# rCSL_vpif_001 register map
Vendor: Texas Instruments
Peripheral module from a debugger description file (folder OMAPL138_C6748).
Registers are 32-bit, access not given, reset 0x0 unless marked. A register's access mark holds for its fields unless they carry their own. Offsets are as the file gives them; lines under a group give offsets from that group; [hi:lo] are bit positions; {n}, {i} and the like mark numbered series; 'fields as' and 'values as' point back to an identical list; <NAME> marks a mode.

## VPIF
0x00 REVID ro reset 0x4C080A01 — VPIF Identification
  [31:0] REV
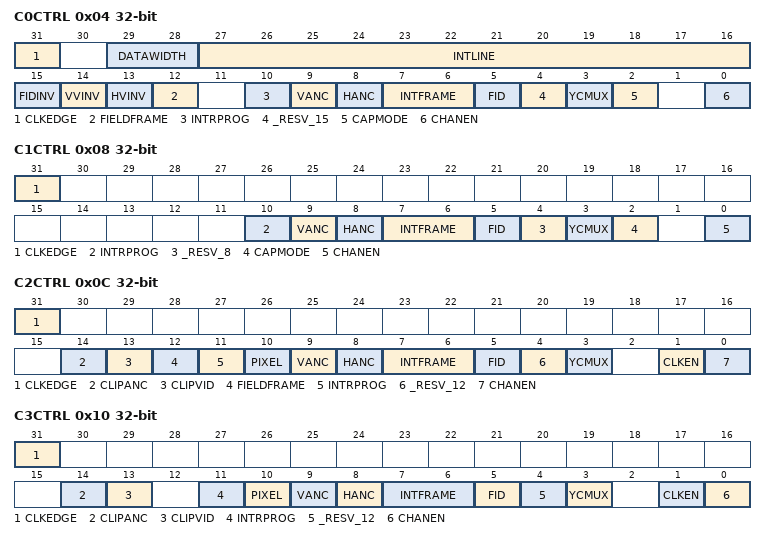
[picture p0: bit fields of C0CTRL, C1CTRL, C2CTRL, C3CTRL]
0x04 C0CTRL — Channel#0 control register
  [31] CLKEDGE rw — This register defines timing relationship between data phase and clock edge for video input data which is connected to VPIF channel 0 (at the chip-pin level). Edge control is carried out outside the module (just register signal is only asserted from the module) 0: data phase is changed at rising edge of the input clock 1: data phase is changed at falling edge of the input clock
    0=RISE (data phase is changed at rising edge of the input clock); 1=FALL (data phase is changed at falling edge of the input clock)
  [29:28] DATAWIDTH rw — Data bit width 00: 8 bit/pixel 01: 10 bit/pixel 10: 12 bit/pixel
    0=8BIT (8-bit format); 1=10BIT (10-bit format); 2=12BIT (12-bit format)
  [27:16] INTLINE rw — Line interrrupt interval
  [15] FIDINV rw — Field ID polarity
    0=DISABLE (No inversion); 1=ENABLE (Invert incoming field ID signal inside the module)
  [14] VVINV rw — Vertical pixel valid signal polarity control
    0=DISABLE (No inversion); 1=ENABLE (Invert incoming vertical pixel valid signal inside the module)
  [13] HVINV rw — Horizontal pixel valid signal polarity control
    0=DISABLE (No inversion); 1=ENABLE (Invert incoming horizontal pixel valid signal inside the module)
  [12] FIELDFRAME rw — SDRAM storage mode of input picture
    0=FIELD (Field storage); 1=FRAME (Frame storage)
  [10] INTRPROG rw — Output display format
    0=INTERLACED (Interlaced, 60 field/sec); 1=PROGRESSIVE (Progressive, 30 frame/sec)
  [9] VANC rw — Channel#0 Vertical Ancillary data enable 0:Vertical ancillary Data not supported 1:Vertical ancillary data is supported
    0=DISABLE (Vertical ancillary data disable); 1=ENABLE (Vertical ancillary data enable)
  [8] HANC rw — Channel#0 Horizontal Ancillary data enable 0: Horizontal ancillary Data not supported 1:Horizontal ancillary data is supported
    0=DISABLE (Horizontal ancillary data disable); 1=ENABLE (Horizontal ancillary data enable)
  [7:6] INTFRAME rw — Channel#0 Frame level interrupt to CPU 00: top field V-sync only 01: bottom field V-sync only 10: both top and bottom field V-sync 11: Reserved
    0=TOP (Top field V-sync only); 1=BOTTOM (Bottom field V-sync); 2=BOTH (Top and Bottom field)
  [5] FID ro — Channel#0 Field Identification
    0=TOP; 1=BOTTOM
  [4] _RESV_15 — SDRAM address format control register 0: raster scanning mode 1: sub-picture mode (access N)
  [3] YCMUX rw — Channel#0 input data format 0: Y/C non-multiplexed mode 1: Y/C multiplexed mode
    0=DISABLE (Channel#0 Non-multiplexed Y/C); 1=ENABLE (Channel#0 Y/C multiplexed)
  [2] CAPMODE rw — Channel#0 data mode to be processed 0x: BT. video (Y/C format) capture mode (sync signal is multiplexed). 1x: CCD/CMOS data capture mode (sync signal is independently prepared).
    0=BTYC (BT. video (Y/C format) capture mode); 1=CCDCMOS (CCD/CMOS data capture mode)
  [0] CHANEN rw — Channel#0 VPIF enable 0: Channel#0 VPIF module inactivated 1: Channel#0 VPIF module activated
    0=DISABLE (Channel#0 disable); 1=ENABLE (Channel#0 enable)
0x08 C1CTRL — Channel#1 control register
  [31] CLKEDGE rw — This register defines timing relationship between data phase and clock edge for video input data which is connected to VPIF channel 1 (at the chip-pin level). Edge control is carried out outside the module (just register signal is only asserted from the module) 0: data phase is changed at rising edge of the input clock 1: data phase is changed at falling edge of the input clock
    values as C0CTRL.CLKEDGE
  [10] INTRPROG rw — Output display format 0: Interlaced (60 [field/sec]) format. 1: Progressive (30 [frame/sec]) format.
    values as C0CTRL.INTRPROG
  [9] VANC rw — Channel#1 Vertical Ancillary data enable 0: Vertical Ancillary Data not supported 1: Vertical ancillary data is supported
    0=DISABLE (Vertical ancillary data disable); 1=ENABLE (Veritical ancillary data enable)
  [8] HANC rw — Channel#1 Horizontal Ancillary data enable 0: Horizontal ancillary Data not supported 1:Horizontal ancillary data is supported
    values as C0CTRL.HANC
  [7:6] INTFRAME rw — Channel#1 Frame level interrupt to CPU 00: top field V-sync only 01: bottom field V-sync only 10: both top and bottom field V-sync 11: Reserved
    values as C0CTRL.INTFRAME
  [5] FID ro — Channel#1 Field Identification
    0=TOP; 1=BOTTOM
  [4] _RESV_8 — SDRAM address format control register 0: raster scanning mode 1: sub-picture mode (access N)
  [3] YCMUX rw — Channel#1 input data format 0: Y/C non-multiplexed mode 1: Y/C multiplexed mode
    0=DISABLE (Channel#1 Non-multiplexed Y/C); 1=ENABLE (Channel#1 Y/C multiplexed)
  [2] CAPMODE rw — Channel#1 data mode to be processed 0x: BT. video (Y/C format) capture mode (sync signal is multiplexed). 1x: CCD/CMOS data capture mode (sync signal is independently prepared).
    values as C0CTRL.CAPMODE
  [0] CHANEN rw — Channel#1 VPIF enable 0: Channel#1 VPIF module inactivated 1: Channel#1 VPIF module activated
    0=DISABLE (Channel#1 disable); 1=ENABLE (Channel#1 enable)
0x0C C2CTRL — Channel#2 control register
  [31] CLKEDGE rw — This register defines timing relationship between data phase and clock edge for video output data which is connected to VPIF channel 2 (at the chip-pin level). Edge control is carried out outside the module (just register signal is only asserted from the module) 0: data phase is changed at rising edge of the input clock 1: data phase is changed at falling edge of the input clock
    values as C0CTRL.CLKEDGE
  [14] CLIPANC rw — Enable clipping support for ancillary data
    0=DISABLE; 1=ENABLE
  [13] CLIPVID rw — Enable clipping support for active video
    0=DISABLE; 1=ENABLE
  [12] FIELDFRAME rw — SDRAM storage mode of output picture 0: field independently stored. 1: frame based.
    0=FIELD (Field storage); 1=FRAME (Frame storage)
  [11] INTRPROG rw — Output display format 0: Interlaced (60 [field/sec]) format. 1: Progressive (30 [frame/sec]) format.
    values as C0CTRL.INTRPROG
  [10] PIXEL rw — Pixel data enable or disable 0: Pixel data disabled 1: Pixel data enabled
    0=DISABLE (Pixel data disabled); 1=ENABLE (Pixel data enabled)
  [9] VANC rw — Channel#2 Vertical Ancillary data enable 0: Vertical Ancillary Data not supported 1: Vertical ancillary data is supported
    values as C1CTRL.VANC
  [8] HANC rw — Channel#2 Horizontal Ancillary data enable 0: Horizontal ancillary Data not supported 1:Horizontal ancillary data is supported
    values as C0CTRL.HANC
  [7:6] INTFRAME rw — Channel#2 Frame level interrupt to CPU 00: top field V-sync only 01: bottom field V-sync only 10: both top and bottom field V-sync 11: Reserved
    values as C0CTRL.INTFRAME
  [5] FID ro — Channel#2 Field Identification
    0=TOP; 1=BOTTOM
  [4] _RESV_12 — SDRAM address format control register 0: raster scanning mode 1: sub-picture mode (access N)
  [3] YCMUX rw — Channel#2 data format to be transmitted 0: Y/C non-multiplexed mode 1: Y/C multiplexed mode
    0=DISABLE (Y/C non-multiplexed mode); 1=ENABLE (Y/C multiplexed mode)
  [1] CLKEN rw — Channel#2 VPIF Clock enable 0: Channel#2 clock inactivated 1: Channel#2 clock activated
    0=DISABLE (Channel#2 clock disable); 1=ENABLE (Channel#2 clock enable)
  [0] CHANEN rw — Channel#2 VPIF enable 0: Channel#2 VPIF module inactivated 1: Channel#2 VPIF module activated
    0=DISABLE (Channel#2 disable); 1=ENABLE (Channel#2 enable)
0x10 C3CTRL — Channel#3 control register
  [31] CLKEDGE rw — This register defines timing relationship between data phase and clock edge for video output data which is connected to VPIF channel 3 (at the chip-pin level). Edge control is carried out outside the module (just register signal is only asserted from the module) 0: data phase is changed at rising edge of the input clock 1: data phase is changed at falling edge of the input clock
    values as C0CTRL.CLKEDGE
  [14] CLIPANC rw — Enable clipping support for ancillary data
    0=DISABLE; 1=ENABLE
  [13] CLIPVID rw — Enable clipping support for active video
    0=DISABLE; 1=ENABLE
  [11] INTRPROG rw — Output display format 0: Interlaced (60 [field/sec]) format. 1: Progressive (30 [frame/sec]) format.
    values as C0CTRL.INTRPROG
  [10] PIXEL rw — Pixel data enable or disable 0: Pixel data disabled 1: Pixel data enabled
    values as C2CTRL.PIXEL
  [9] VANC rw — Channel#3 Vertical Ancillary data enable 0: Vertical Ancillary Data not supported 1: Vertical ancillary data is supported
    values as C1CTRL.VANC
  [8] HANC rw — Channel#3 Horizontal Ancillary data enable 0: Horizontal ancillary Data not supported 1:Horizontal ancillary data is supported
    values as C0CTRL.HANC
  [7:6] INTFRAME rw — Channel#3 Frame level interrupt to CPU 00: top field V-sync only 01: bottom field V-sync only 10: both top and bottom field V-sync 11: Reserved
    values as C0CTRL.INTFRAME
  [5] FID ro — Channel#3 Field Identification
    0=TOP; 1=BOTTOM
  [4] _RESV_12 — SDRAM address format control register 0: raster scanning mode 1: sub-picture mode (access N)
  [3] YCMUX rw — Channel#3 data format to be transmitted 0: Y/C non-multiplexed mode 1: Y/C multiplexed mode
    values as C2CTRL.YCMUX
  [1] CLKEN rw — Channel#3 VPIF Clock enable 0: Channel#3 clock inactivated 1: Channel#3 clock activated
    0=DISABLE (Channel#3 clock disable); 1=ENABLE (Channel#3 clock enable)
  [0] CHANEN rw — Channel#3 VPIF enable 0: Channel#3 VPIF module inactivated 1: Channel#3 VPIF module activated
    0=DISABLE (Channel#3 disable); 1=ENABLE (Channel#3 enable); 1=ERROR (EAV/SAV bit error exist)
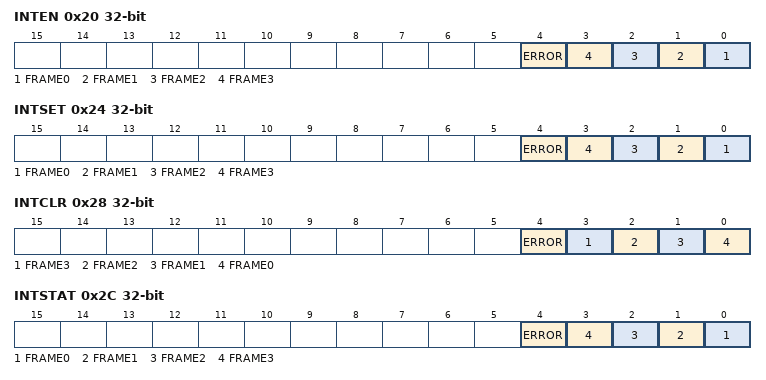
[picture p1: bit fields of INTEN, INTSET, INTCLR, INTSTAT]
0x20 INTEN — Interrupt enable register
  [4] ERROR rw — To activate error interrupt 0: Error interrupt disabled 1: Error interrupt enabled
    0=DISABLE (Error interrupt disable); 1=ENABLE (Error interrupt enabled)
  [n] FRAME{n} rw (n=0..3) — Frame interrupt enable for Channel#{n} 0: Channel#{n} Frame interrupt disable 1: Channel#{n} Frame interrupt enable
    0=DISABLE (Channel#{n} frame interrupt disable); 1=ENABLE (Channel#{n} frame interrupt enable)
0x24 INTSET — Interrupt activation register
  [4] ERROR rw — To activate error interrupt 0: Error interrupt disabled 1: Error interrupt enabled
    0=DISABLE (vpif_inten_error inactivated); 1=ENABLE (vpif_inten_error activated)
  [n] FRAME{n} rw (n=0..3) — Frame interrupt enable for Channel#{n} 0: Channel#{n} Frame interrupt disable 1: Channel#{n} Frame interrupt enable
    0=DISABLE (vpif_inten_frame_ch{n} inactivated); 1=ENABLE (vpif_inten_frame_ch{n} activated)
0x28 INTCLR — Interrupt clear register
  [4] ERROR wo — To activate error interrupt 0: No change 1: Interrupt on vpif_inten_error inactivated
    0=NC (No change); 1=CLR (vpif_inten_error inactivated)
  [3] FRAME3 wo — Frame interrupt enable for Channel#3 0: NC 1: Interrupt on vpif_inten_frame_ch3 inactivated
    0=NC (No change); 1=CLR (vpif_inten_frame_ch3 inactivated)
  [2] FRAME2 wo — Frame interrupt enable for Channel#2 0: NC 1: Channel#2 Frame interrupt enable
    0=NC (No change); 1=CLR (vpif_inten_frame_ch2 inactivated)
  [1] FRAME1 wo — Frame interrupt enable for Channel#1 0: NC 1: Channel#1 Frame interrupt enable
    0=NC (No change); 1=CLR (vpif_inten_frame_ch1 inactivated)
  [0] FRAME0 wo — Frame interrupt enable for Channel#0 0: NC 1: Channel#0 Frame interrupt enable
    0=NC (No change); 1=CLR (vpif_inten_frame_ch0 inactivated)
0x2C INTSTAT — Interrupt Status register
  [all] fields
    0=NOPEND; 1=PEND
  [4] ERROR ro — Error interrupt status 0: Error is not detected so far 1: Error is detected and not checked yet
  [n] FRAME{n} ro (n=0..3) — Frame sync detect for Channel#{n} 0: Channel#{n} Frame sync not detected 1: Channel#{n} Frame sync detected
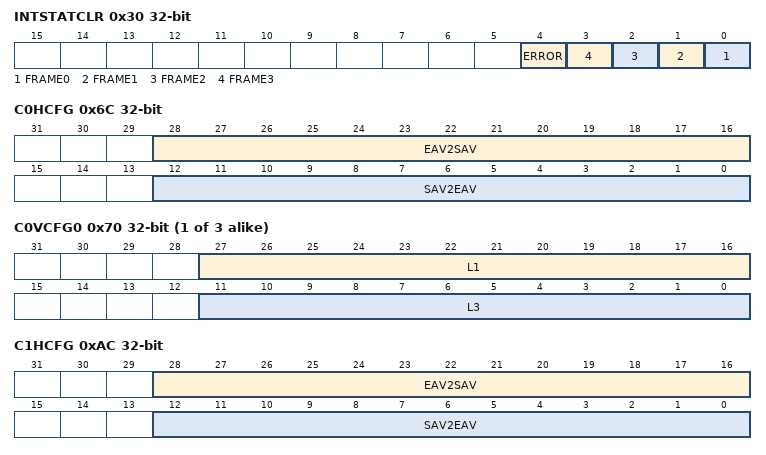
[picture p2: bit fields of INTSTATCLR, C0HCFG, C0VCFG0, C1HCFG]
0x30 INTSTATCLR — Interrupt Status clear register
  [4] ERROR wo — Status clear register 0: No Change 1: VPIF status clear resiger
    0=NC (No change); 1=CLR (vpif_status clear register)
  [n] FRAME{n} wo (n=0..3) — Channel#{n} status clear register 0: No change 1: Channel#{n} status clear register
    0=NC (Channel#{n} No change); 1=CLR (Channel#{n} clear register)
0x34 EMUCTRL — Emulation suspend control register
  [0] FREE rw — Peripheral respond to emulation suspend signal control 0: Emulation control based on vpif_emulsusp_soft 1: Emulation configuration ignore
    0=SUSP; 1=FREE
0x38 REQSIZE — VPIF DMA request unit size control register
  [8:0] BYTES rw — DMA request unit size 000100000: 32 byte 001000000: 64 byte 010000000: 128 byte 100000000: 256 byte
{0x40+0x40*i} C{i}TLUMA rw (i=0..2) — Channel#{i} top start add register for luma
  [31:0] C{i}TLUMA — Defines Channel#{i} top start address for luma
0x44 C0BLUMA rw — Channel#0 btm start add register for luma
  [31:0] C0BLUMA — Defines Channel#0 btm start address for luma
{0x48+0x40*i} C{i}TCHROMA rw (i=0..2) — Channel#{i} top start add register for chroma
  [31:0] C{i}TCHROMA — Defines Channel#{i} top start address for chroma
{0x4C+0x40*i} C{i}BCHROMA rw (i=0..2) — Channel#{i} btm start add register for chroma
  [31:0] C{i}BCHROMA — Defines Channel#{i} btm start address for chroma
{0x50+0x40*i} C{i}THANC rw (i=0..2) — Channel#{i} top start add register for hanc
  [31:0] C{i}THANC — Defines Channel#{i} top start address for hanc
0x54 C0BHANC rw — Channel#0 btm start add register for hanc
  [31:0] C0BHANC — Defines Channel#0 btm start address for hanc
{0x58+0x40*i} C{i}TVANC rw (i=0..2) — Channel#{i} top start add register for vanc
  [31:0] C{i}TVANC — Defines Channel#{i} top start address for vanc
{0x5C+0x40*i} C{i}BVANC rw (i=0..2) — Channel#{i} btm start add register for vanc
  [31:0] C{i}BVANC — Defines Channel#{i} btm start address for vanc
{0x64+0x40*i} C{i}IMGOFFSET rw (i=0..2) — Channel#{i} image offset address
{0x68+0x40*i} C{i}HANCOFFSET rw (i=0..2) — Channel#{i} hanc offset address
0x6C C0HCFG — Channel#0 horizontal configuration
  [28:16] EAV2SAV rw — Distance between EAV to SAV
  [12:0] SAV2EAV rw — Distance between SAV to EAV
{0x70+4i} C0VCFG{i} (i=0..2) — Channel#0 vertical data size configuration {i}
  [27:16] L{4i+1} rw — L{4i+1} register configuraion
  [11:0] L{4i+3} rw — L{4i+3} register configuration
0x7C C0VSIZE — Channel#0 vertical image size of incoming video data
  [11:0] VSIZE rw — Vertical image size
0x84 C1BLUMA rw — Channel#1 btm start add register for luma
  [31:0] C1BLUMA — Defines Channel#1 btm start address for luma
0x94 C1BHANC rw — Channel#0 btm start add register for hanc
  [31:0] C1BHANC — Defines Channel#1 btm start address for hanc
0xAC C1HCFG — Channel#1 horizontal configuration
  fields as C0HCFG
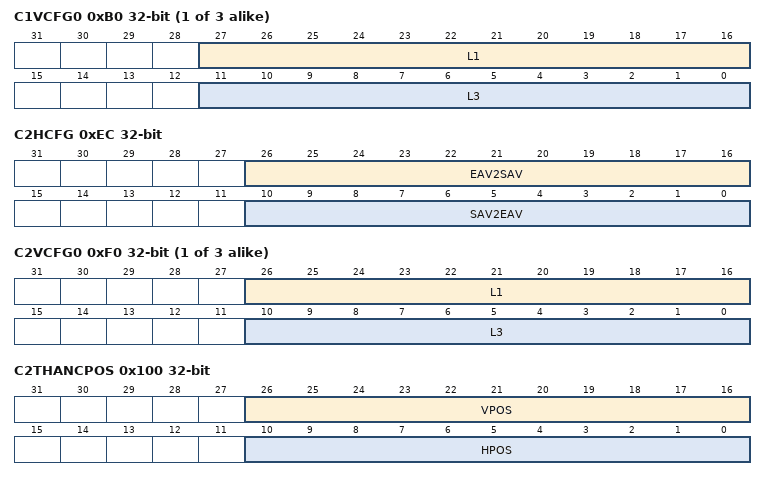
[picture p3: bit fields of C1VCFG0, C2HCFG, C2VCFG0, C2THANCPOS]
{0xB0+4i} C1VCFG{i} (i=0..2) — Channel#1 vertical data size configuration {i}
  fields as C0VCFG0
0xBC C1VSIZE — Channel#1 vertical image size
  [11:0] VSIZE rw — Vertical image size
0xC4 C2BLUMA rw — Channel#1 btm start add register for luma
  [31:0] C2BLUMA — Defines Channel#2 btm start address for luma
0xD4 C2BHANC rw — Channel#2 btm start add register for hanc
  [31:0] C2BHANC — Defines Channel#2 btm start address for hanc
0xEC C2HCFG — Channel#2 horizontal configuration
  [26:16] EAV2SAV rw — Distance between EAV to SAV
  [10:0] SAV2EAV rw — Distance between SAV to EAV
{0xF0+4i} C2VCFG{i} (i=0..2) — Channel#2 vertical data size configuration {i}
  [26:16] L{4i+1} rw — L{4i+1} register configuraion
  [10:0] L{4i+3} rw — L{4i+3} register configuration
0xFC C2VSIZE — Channel#2 vertical image size
  [10:0] VSIZE rw — Vertical image size of incoming video data
0x100 C2THANCPOS — Channel#2 Horizontal ancillary data insertion top start position
  [26:16] VPOS rw — Channel#2 veritical start position for hanc0
  [10:0] HPOS rw — Channel#2 horizontal start position for hanc0
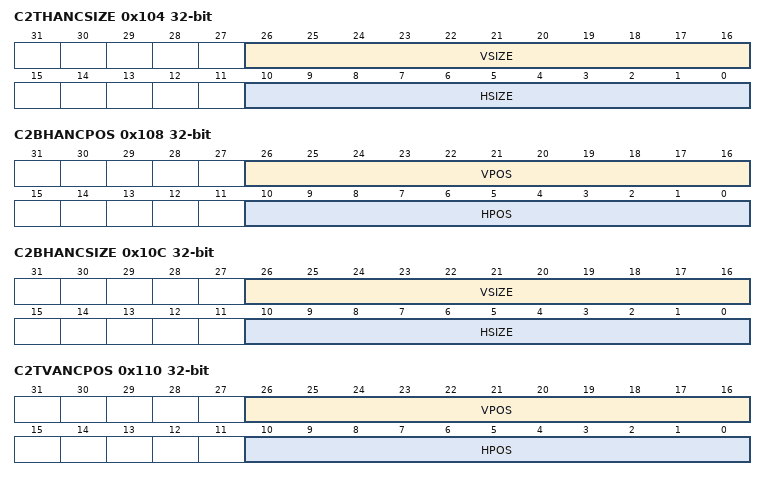
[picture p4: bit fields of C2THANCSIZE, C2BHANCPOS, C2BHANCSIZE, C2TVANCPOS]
0x104 C2THANCSIZE — Channel#2 Horizontal ancillary data top size
  [26:16] VSIZE rw — Channel#2 hanc0 vertical size
  [10:0] HSIZE rw — Channel#2 hanc0 horizontal size
0x108 C2BHANCPOS — Channel#2 Horizontal ancillary data insertion btm start position
  [26:16] VPOS rw — Channel#2 veritical start position for hanc1
  [10:0] HPOS rw — Channel#2 horizontal start position for hanc1
0x10C C2BHANCSIZE — Channel#2 Horizontal ancillary data btm size
  [26:16] VSIZE rw — Channel#2 hanc1 vertical size
  [10:0] HSIZE rw — Channel#2 hanc1 horizontal size
0x110 C2TVANCPOS — Channel#2 Vertical ancillary data insertion top start position
  [26:16] VPOS rw — Channel#2 veritical start position for vanc0
  [10:0] HPOS rw — Channel#2 horizontal start position for vanc0
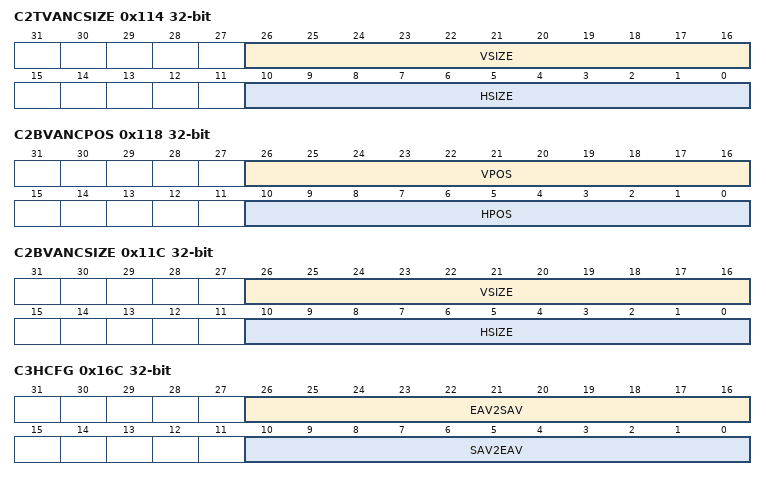
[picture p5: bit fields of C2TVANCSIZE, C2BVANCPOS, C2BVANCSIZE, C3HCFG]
0x114 C2TVANCSIZE — Channel#2 Vertical ancillary data top size
  [26:16] VSIZE rw — Channel#2 vanc0 vertical size
  [10:0] HSIZE rw — Channel#2 vanc0 horizontal size
0x118 C2BVANCPOS — Channel#2 Vertical ancillary data insertion btm start position
  [26:16] VPOS rw — Channel#2 veritical start position for vanc1
  [10:0] HPOS rw — Channel#2 vertical start position for vanc1
0x11C C2BVANCSIZE — Channel#2 Vertical ancillary data btm size
  [26:16] VSIZE rw — Channel#2 vanc1 vertical size
  [10:0] HSIZE rw — Channel#2 vanc1 horizontal size
0x140 C3TLUMA rw — Channel#3 top start add register for luma
  [31:0] C3TLUMA — Defines Channel#3 top start address for luma
0x144 C3BLUMA rw — Channel#3 btm start add register for luma
  [31:0] C3BLUMA — Defines Channel#3 btm start address for luma
0x148 C3TCHROMA rw — Channel#3 top start add register for chroma
  [31:0] C3TCHROMA — Defines Channel#3 top start address for chroma
0x14C C3BCHROMA rw — Channel#3 btm start add register for chroma
  [31:0] C3BCHROMA — Defines Channel#3 btm start address for chroma
0x150 C3THANC rw — Channel#3 top start add register for hanc
  [31:0] C3THANC — Defines Channel#3 top start address for hanc
0x154 C3BHANC rw — Channel#3 btm start add register for hanc
  [31:0] C3BHANC — Defines Channel#3 btm start address for hanc
0x158 C3TVANC rw — Channel#3 top start add register for vanc
  [31:0] C3TVANC — Defines Channel#3 top start address for vanc
0x15C C3BVANC rw — Channel#3 btm start add register for vanc
  [31:0] C3BVANC — Defines Channel#3 btm start address for vanc
0x164 C3IMGOFFSET rw — Channel#3 image offset address
0x168 C3HANCOFFSET rw — Channel#3 hanc offset address
0x16C C3HCFG — Channel#3 horizontal configuration
  fields as C2HCFG
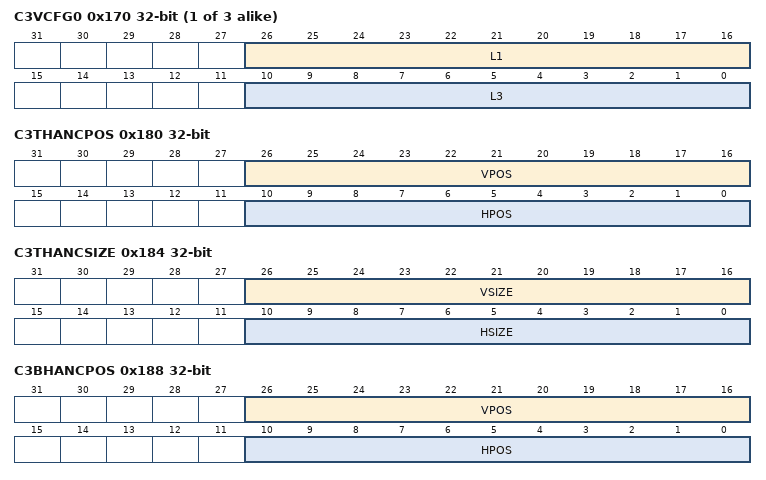
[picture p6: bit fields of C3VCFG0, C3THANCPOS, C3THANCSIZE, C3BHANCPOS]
{0x170+4i} C3VCFG{i} (i=0..2) — Channel#3 vertical data size configuration {i}
  fields as C2VCFG0
0x17C C3VSIZE — Channel#3 vertical Image size
  [10:0] VSIZE rw — L12 register configuraion
0x180 C3THANCPOS — Channel#3 Horizontal ancillary data insertion top start position
  [26:16] VPOS rw — Channel#3 veritical start position for hanc0
  [10:0] HPOS rw — Channel#3 horizontal start position for hanc0
0x184 C3THANCSIZE — Channel#3 Horizontal ancillary data top size
  [26:16] VSIZE rw — Channel#3 hanc0 vertical size
  [10:0] HSIZE rw — Channel#3 hanc0 horizontal size
0x188 C3BHANCPOS — Channel#3 Horizontal ancillary data insertion btm start position
  [26:16] VPOS rw — Channel#3 veritical start position for hanc1
  [10:0] HPOS rw — Channel#3 horizontal start position for hanc1
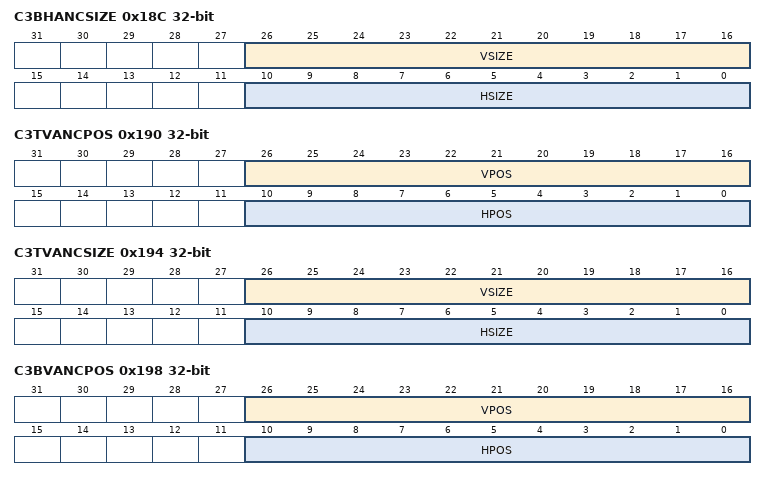
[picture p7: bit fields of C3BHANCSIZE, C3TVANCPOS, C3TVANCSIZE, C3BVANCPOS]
0x18C C3BHANCSIZE — Channel#3 Horizontal ancillary data btm size
  [26:16] VSIZE rw — Channel#3 hanc1 vertical size
  [10:0] HSIZE rw — Channel#3 hanc1 horizontal size
0x190 C3TVANCPOS — Channel#3 Vertical ancillary data insertion top start position
  [26:16] VPOS rw — Channel#3 veritical start position for vanc0
  [10:0] HPOS rw — Channel#3 horizontal start position for vanc0
0x194 C3TVANCSIZE — Channel#3 Vertical ancillary data top size
  [26:16] VSIZE rw — Channel#3 vanc0 vertical size
  [10:0] HSIZE rw — Channel#3 vanc0 horizontal size
0x198 C3BVANCPOS — Channel#3 Vertical ancillary data insertion btm start position
  [26:16] VPOS rw — Channel#3 veritical start position for vanc1
  [10:0] HPOS rw — Channel#3 vertical start position for vanc1
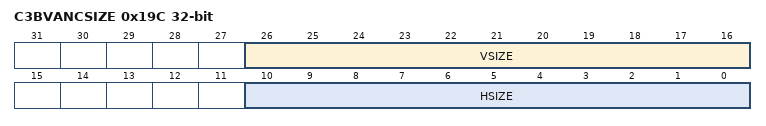
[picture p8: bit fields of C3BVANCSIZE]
0x19C C3BVANCSIZE — Channel#3 Vertical ancillary data btm size
  [26:16] VSIZE rw — Channel#3 vanc1 vertical size
  [10:0] HSIZE rw — Channel#3 vanc1 horizontal size
